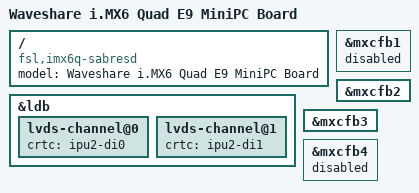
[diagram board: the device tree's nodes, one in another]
/*
 * Copyright 2019 Ovidiu Mihalachi <ovidiu.mihalachi@gmail.com>
 *
 * The code contained herein is licensed under the GNU General Public
 * License. You may obtain a copy of the GNU General Public License
 * Version 2 or later at the following locations:
 *
 * http://www.opensource.org/licenses/gpl-license.html
 * http://www.gnu.org/copyleft/gpl.html
 */


/dts-v1/;

#include "imx6q.dtsi"
#include "imx6q-embedsky.dtsi"

/ {
	model = "Waveshare i.MX6 Quad E9 MiniPC Board";
	compatible = "fsl,imx6q-sabresd", "fsl,imx6q";
};

&ldb {
        lvds-channel@0 {
                crtc = "ipu2-di0";
        };
        lvds-channel@1 {
                crtc = "ipu2-di1";
        };
};

&mxcfb1 {
	status = "disabled";
};

&mxcfb2 {
	status = "okay";
};

&mxcfb3 {
	status = "okay";
};

&mxcfb4 {
	status = "disabled";
};
